# STM32F745 register map
File version: 1.6
CPU: CM7 r0p1, little endian, MPU, FPU, 4 interrupt priority bits
Registers are 32-bit, read-write, reset 0x0 unless marked. A register's access mark holds for its fields unless they carry their own. Offsets are from the block's base; [hi:lo] are bit positions; {n}, {i} and the like mark numbered series.

## DBGMCU — Debug support
Base 0xE0042000
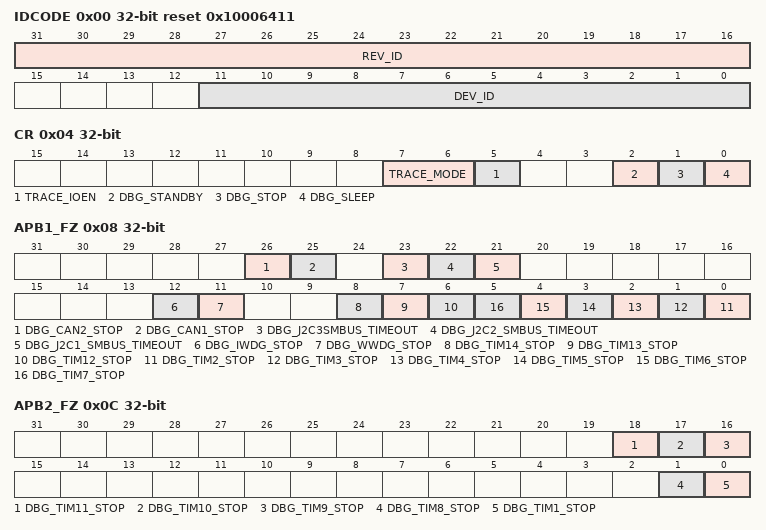
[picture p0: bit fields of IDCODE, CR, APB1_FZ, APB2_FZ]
0x00 IDCODE ro reset 0x10006411
  [31:16] REV_ID, [11:0] DEV_ID
0x04 CR — Control Register
  [7:6] TRACE_MODE, [5] TRACE_IOEN, [2] DBG_STANDBY, [1] DBG_STOP, [0] DBG_SLEEP
0x08 APB1_FZ — Debug MCU APB1 Freeze registe
  [26] DBG_CAN2_STOP
  [25] DBG_CAN1_STOP
  [23] DBG_J2C3SMBUS_TIMEOUT
  [22] DBG_J2C2_SMBUS_TIMEOUT
  [21] DBG_J2C1_SMBUS_TIMEOUT
  [12] DBG_IWDG_STOP — DBG_IWDEG_STOP
  [11] DBG_WWDG_STOP
  [8] DBG_TIM14_STOP
  [7] DBG_TIM13_STOP
  [6] DBG_TIM12_STOP
  [n-2] DBG_TIM{n}_STOP (n=2..7)
0x0C APB2_FZ — Debug MCU APB2 Freeze registe
  [18] DBG_TIM11_STOP — TIM11 counter stopped when core is halted
  [17] DBG_TIM10_STOP — TIM10 counter stopped when core is halted
  [16] DBG_TIM9_STOP — TIM9 counter stopped when core is halted
  [1] DBG_TIM8_STOP — TIM8 counter stopped when core is halted
  [0] DBG_TIM1_STOP — TIM1 counter stopped when core is halted

## SYSCFG — System configuration controller
Base 0x40013800
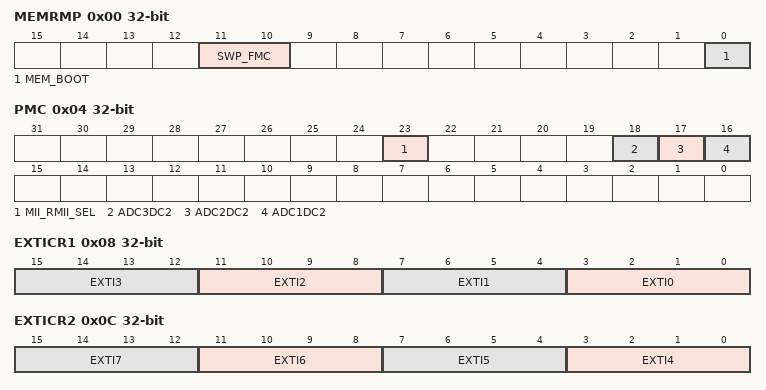
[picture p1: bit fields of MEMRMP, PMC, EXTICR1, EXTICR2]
0x00 MEMRMP — memory remap register
  [11:10] SWP_FMC — FMC memory mapping swap
  [0] MEM_BOOT — Memory mapping selection
0x04 PMC — peripheral mode configuration register
  [23] MII_RMII_SEL — Ethernet PHY interface selection
  [18] ADC3DC2
  [17] ADC2DC2
  [16] ADC1DC2
0x08 EXTICR1 — external interrupt configuration register 1
  [4n+3:4n] EXTI{n} (n=0..3) — EXTI x configuration (x = 0 to 3)
0x0C EXTICR2 — external interrupt configuration register 2
  [4n-13:4n-16] EXTI{n} (n=4..7) — EXTI x configuration (x = 4 to 7)
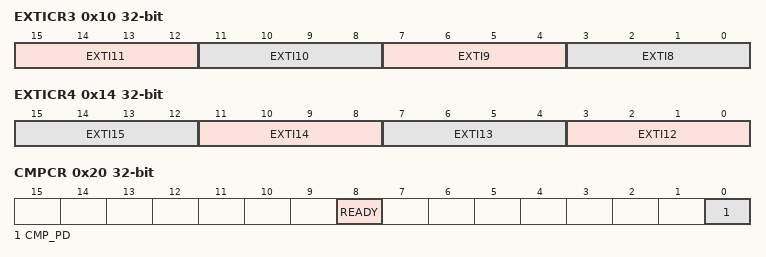
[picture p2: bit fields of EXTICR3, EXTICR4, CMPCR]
0x10 EXTICR3 — external interrupt configuration register 3
  [15:12] EXTI11 — EXTI x configuration (x = 8 to 11)
  [11:8] EXTI10
  [7:4] EXTI9 — EXTI x configuration (x = 8 to 11)
  [3:0] EXTI8 — EXTI x configuration (x = 8 to 11)
0x14 EXTICR4 — external interrupt configuration register 4
  [4n-45:4n-48] EXTI{n} (n=12..15) — EXTI x configuration (x = 12 to 15)
0x20 CMPCR ro — Compensation cell control register
  [8] READY
  [0] CMP_PD — Compensation cell power-down

## PWR — Power control
Base 0x40007000
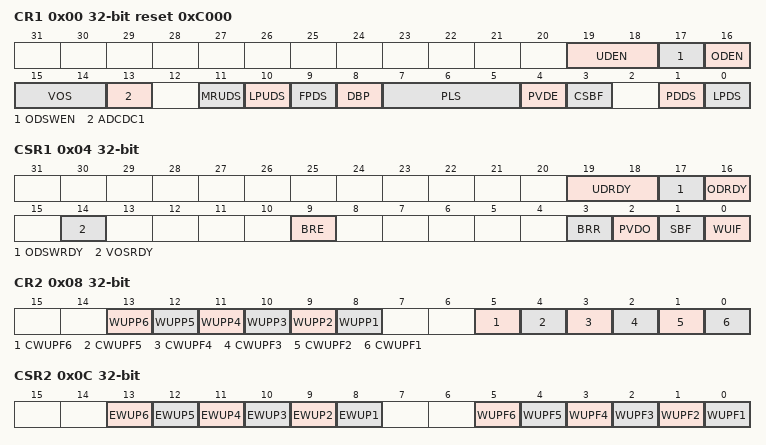
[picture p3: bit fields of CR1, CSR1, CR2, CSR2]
0x00 CR1 reset 0xC000 — power control register
  [19:18] UDEN — Under-drive enable in stop mode
  [17] ODSWEN — Over-drive switching enabled
  [16] ODEN — Over-drive enable
  [15:14] VOS — Regulator voltage scaling output selection
    1=SCALE3 (Scale 3 mode); 2=SCALE2 (Scale 2 mode); 3=SCALE1 (Scale 1 mode (reset value))
  [13] ADCDC1
  [11] MRUDS — Main regulator in deepsleep under-drive mode
  [10] LPUDS — Low-power regulator in deepsleep under-drive mode
  [9] FPDS — Flash power down in Stop mode
  [8] DBP — Disable backup domain write protection
  [7:5] PLS — PVD level selection
  [4] PVDE — Power voltage detector enable
  [3] CSBF — Clear standby flag
  [1] PDDS — Power down deepsleep
    0=STOP_MODE (Enter Stop mode when the CPU enters deepsleep); 1=STANDBY_MODE (Enter Standby mode when the CPU enters deepsleep)
  [0] LPDS — Low-power deep sleep
0x04 CSR1 access per field — power control/status register
  [19:18] UDRDY rw — Under-drive ready flag
  [17] ODSWRDY rw — Over-drive mode switching ready
  [16] ODRDY rw — Over-drive mode ready
  [14] VOSRDY rw — Regulator voltage scaling output selection ready bit
  [9] BRE rw — Backup regulator enable
  [3] BRR ro — Backup regulator ready
  [2] PVDO ro — PVD output
  [1] SBF ro — Standby flag
  [0] WUIF ro — Wakeup internal flag
0x08 CR2 access per field — power control register
  [13] WUPP6 rw — Wakeup pin polarity bit for PI11
  [12] WUPP5 rw — Wakeup pin polarity bit for PI8
  [11] WUPP4 rw — Wakeup pin polarity bit for PC13
  [10] WUPP3 rw — Wakeup pin polarity bit for PC1
  [9] WUPP2 rw — Wakeup pin polarity bit for PA2
  [8] WUPP1 rw — Wakeup pin polarity bit for PA0
  [5] CWUPF6 ro — Clear Wakeup Pin flag for PI11
  [4] CWUPF5 ro — Clear Wakeup Pin flag for PI8
  [3] CWUPF4 ro — Clear Wakeup Pin flag for PC13
  [2] CWUPF3 ro — Clear Wakeup Pin flag for PC1
  [1] CWUPF2 ro — Clear Wakeup Pin flag for PA2
  [0] CWUPF1 ro — Clear Wakeup Pin flag for PA0
0x0C CSR2 access per field — power control/status register
  [13] EWUP6 rw — Enable Wakeup pin for PI11
  [12] EWUP5 rw — Enable Wakeup pin for PI8
  [11] EWUP4 rw — Enable Wakeup pin for PC13
  [10] EWUP3 rw — Enable Wakeup pin for PC1
  [9] EWUP2 rw — Enable Wakeup pin for PA2
  [8] EWUP1 rw — Enable Wakeup pin for PA0
  [5] WUPF6 ro — Wakeup Pin flag for PI11
  [4] WUPF5 ro — Wakeup Pin flag for PI8
  [3] WUPF4 ro — Wakeup Pin flag for PC13
  [2] WUPF3 ro — Wakeup Pin flag for PC1
  [1] WUPF2 ro — Wakeup Pin flag for PA2
  [0] WUPF1 ro — Wakeup Pin flag for PA0
